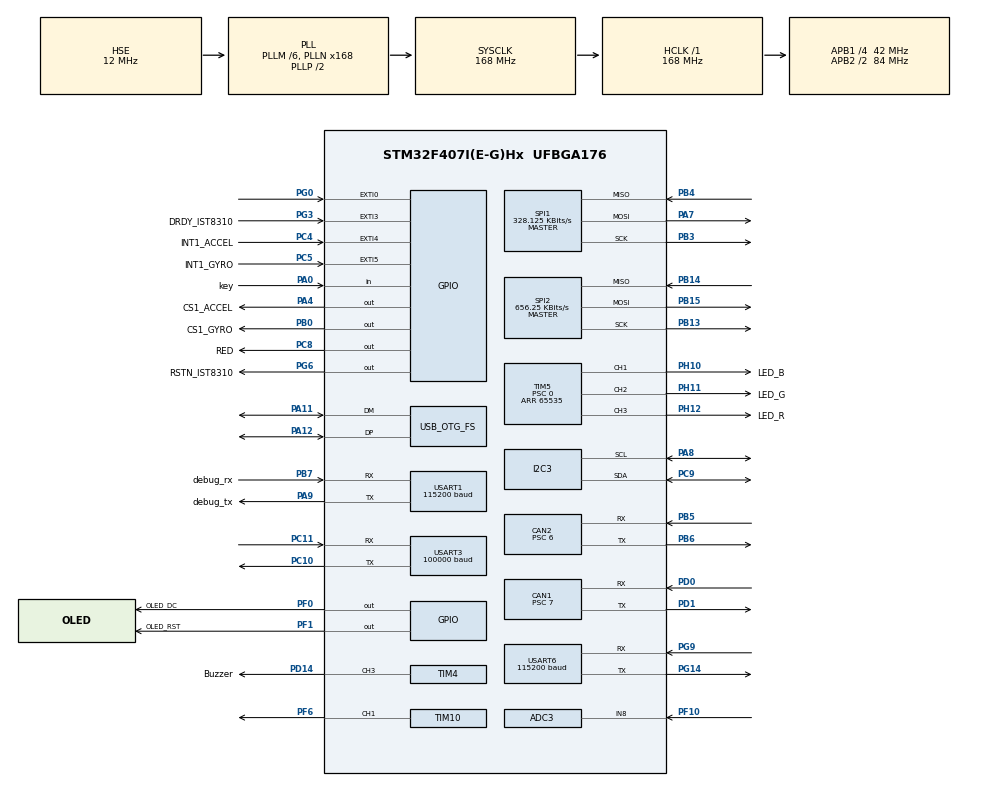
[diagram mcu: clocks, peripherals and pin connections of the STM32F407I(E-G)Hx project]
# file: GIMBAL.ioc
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ADC1.Channel-0\#ChannelRegularConversion=ADC_CHANNEL_TEMPSENSOR
ADC1.NbrOfConversionFlag=1
ADC1.Rank-0\#ChannelRegularConversion=1
ADC1.SamplingTime-0\#ChannelRegularConversion=ADC_SAMPLETIME_3CYCLES
ADC1.master=1
ADC3.Channel-0\#ChannelRegularConversion=ADC_CHANNEL_8
ADC3.NbrOfConversionFlag=1
ADC3.Rank-0\#ChannelRegularConversion=1
ADC3.SamplingTime-0\#ChannelRegularConversion=ADC_SAMPLETIME_3CYCLES
CAN1.ABOM=ENABLE
CAN1.AWUM=ENABLE
CAN1.BS1=CAN_BS1_3TQ
CAN1.BS2=CAN_BS2_2TQ
CAN1.CalculateTimeQuantum=166.66666666666669
CAN1.NART=ENABLE
CAN1.Prescaler=7
CAN2.ABOM=ENABLE
CAN2.AWUM=ENABLE
CAN2.BS1=CAN_BS1_4TQ
CAN2.BS2=CAN_BS2_2TQ
CAN2.CalculateTimeQuantum=142.85714285714286
CAN2.Prescaler=6
Dma.Request0=SPI1_RX
Dma.Request1=SPI1_TX
Dma.Request2=USART1_TX
Dma.Request3=USART3_RX
Dma.Request4=USART1_RX
Dma.Request5=USART6_RX
Dma.Request6=USART6_TX
Dma.SPI1_RX.0.Direction=DMA_PERIPH_TO_MEMORY
Dma.SPI1_RX.0.FIFOMode=DMA_FIFOMODE_DISABLE
Dma.SPI1_RX.0.Instance=DMA2_Stream2
Dma.SPI1_RX.0.MemDataAlignment=DMA_MDATAALIGN_BYTE
Dma.SPI1_RX.0.MemInc=DMA_MINC_ENABLE
Dma.SPI1_RX.0.Mode=DMA_NORMAL
Dma.SPI1_RX.0.PeriphDataAlignment=DMA_PDATAALIGN_BYTE
Dma.SPI1_RX.0.PeriphInc=DMA_PINC_DISABLE
Dma.SPI1_RX.0.Priority=DMA_PRIORITY_VERY_HIGH
Dma.SPI1_TX.1.Direction=DMA_MEMORY_TO_PERIPH
Dma.SPI1_TX.1.FIFOMode=DMA_FIFOMODE_DISABLE
Dma.SPI1_TX.1.Instance=DMA2_Stream3
Dma.SPI1_TX.1.MemDataAlignment=DMA_MDATAALIGN_BYTE
Dma.SPI1_TX.1.MemInc=DMA_MINC_ENABLE
Dma.SPI1_TX.1.Mode=DMA_NORMAL
Dma.SPI1_TX.1.PeriphDataAlignment=DMA_PDATAALIGN_BYTE
Dma.SPI1_TX.1.PeriphInc=DMA_PINC_DISABLE
Dma.SPI1_TX.1.Priority=DMA_PRIORITY_HIGH
Dma.USART1_RX.4.Direction=DMA_PERIPH_TO_MEMORY
Dma.USART1_RX.4.FIFOMode=DMA_FIFOMODE_DISABLE
Dma.USART1_RX.4.Instance=DMA2_Stream5
Dma.USART1_RX.4.MemDataAlignment=DMA_MDATAALIGN_BYTE
Dma.USART1_RX.4.MemInc=DMA_MINC_ENABLE
Dma.USART1_RX.4.Mode=DMA_CIRCULAR
Dma.USART1_RX.4.PeriphDataAlignment=DMA_PDATAALIGN_BYTE
Dma.USART1_RX.4.PeriphInc=DMA_PINC_DISABLE
Dma.USART1_RX.4.Priority=DMA_PRIORITY_LOW
Dma.USART1_TX.2.Direction=DMA_MEMORY_TO_PERIPH
Dma.USART1_TX.2.FIFOMode=DMA_FIFOMODE_DISABLE
Dma.USART1_TX.2.Instance=DMA2_Stream7
Dma.USART1_TX.2.MemDataAlignment=DMA_MDATAALIGN_BYTE
Dma.USART1_TX.2.MemInc=DMA_MINC_ENABLE
Dma.USART1_TX.2.Mode=DMA_NORMAL
Dma.USART1_TX.2.PeriphDataAlignment=DMA_PDATAALIGN_BYTE
Dma.USART1_TX.2.PeriphInc=DMA_PINC_DISABLE
Dma.USART1_TX.2.Priority=DMA_PRIORITY_LOW
Dma.USART3_RX.3.Direction=DMA_PERIPH_TO_MEMORY
Dma.USART3_RX.3.FIFOMode=DMA_FIFOMODE_DISABLE
Dma.USART3_RX.3.Instance=DMA1_Stream1
Dma.USART3_RX.3.MemDataAlignment=DMA_MDATAALIGN_BYTE
Dma.USART3_RX.3.MemInc=DMA_MINC_ENABLE
Dma.USART3_RX.3.Mode=DMA_CIRCULAR
Dma.USART3_RX.3.PeriphDataAlignment=DMA_PDATAALIGN_BYTE
Dma.USART3_RX.3.PeriphInc=DMA_PINC_DISABLE
Dma.USART3_RX.3.Priority=DMA_PRIORITY_MEDIUM
Dma.USART6_RX.5.Direction=DMA_PERIPH_TO_MEMORY
Dma.USART6_RX.5.FIFOMode=DMA_FIFOMODE_DISABLE
Dma.USART6_RX.5.Instance=DMA2_Stream1
Dma.USART6_RX.5.MemDataAlignment=DMA_MDATAALIGN_BYTE
Dma.USART6_RX.5.MemInc=DMA_MINC_ENABLE
Dma.USART6_RX.5.Mode=DMA_CIRCULAR
Dma.USART6_RX.5.PeriphDataAlignment=DMA_PDATAALIGN_BYTE
Dma.USART6_RX.5.PeriphInc=DMA_PINC_DISABLE
Dma.USART6_RX.5.Priority=DMA_PRIORITY_MEDIUM
Dma.USART6_TX.6.Direction=DMA_MEMORY_TO_PERIPH
Dma.USART6_TX.6.FIFOMode=DMA_FIFOMODE_DISABLE
Dma.USART6_TX.6.Instance=DMA2_Stream6
Dma.USART6_TX.6.MemDataAlignment=DMA_MDATAALIGN_BYTE
Dma.USART6_TX.6.MemInc=DMA_MINC_ENABLE
Dma.USART6_TX.6.Mode=DMA_NORMAL
Dma.USART6_TX.6.PeriphDataAlignment=DMA_PDATAALIGN_BYTE
Dma.USART6_TX.6.PeriphInc=DMA_PINC_DISABLE
Dma.USART6_TX.6.Priority=DMA_PRIORITY_HIGH
FREERTOS.INCLUDE_eTaskGetState=1
FREERTOS.INCLUDE_pcTaskGetTaskName=1
FREERTOS.INCLUDE_uxTaskGetStackHighWaterMark=1
FREERTOS.INCLUDE_vTaskCleanUpResources=1
FREERTOS.INCLUDE_vTaskDelayUntil=1
FREERTOS.INCLUDE_xEventGroupSetBitFromISR=1
FREERTOS.INCLUDE_xQueueGetMutexHolder=1
FREERTOS.INCLUDE_xSemaphoreGetMutexHolder=1
FREERTOS.INCLUDE_xTaskAbortDelay=1
FREERTOS.INCLUDE_xTaskGetCurrentTaskHandle=1
FREERTOS.INCLUDE_xTaskGetHandle=1
FREERTOS.INCLUDE_xTimerPendFunctionCall=1
FREERTOS.Tasks01=test,0,128,test_task,As weak,NULL,Dynamic,NULL,NULL;Debug_Task,0,128,Debug,Default,NULL,Dynamic,NULL,NULL;IMU_Send_Task,2,128,IMU_Send,Default,NULL,Dynamic,NULL,NULL;Can2_Rei_Task,1,128,Can2_Reivece,Default,NULL,Dynamic,NULL,NULL;CAN1,1,128,CAN1_R,Default,NULL,Dynamic,NULL,NULL
FREERTOS.configTOTAL_HEAP_SIZE=24576
I2C3.I2C_Mode=I2C_Fast
Mcu.Family=STM32F4
Mcu.Name=STM32F407I(E-G)Hx
Mcu.Package=UFBGA176
NVIC.CAN1_RX0_IRQn=true\:5\:0\:true\:false\:true\:true\:true\:true
NVIC.CAN2_RX0_IRQn=true\:5\:0\:true\:false\:true\:true\:true\:true
NVIC.DMA1_Stream1_IRQn=true\:0\:0\:false\:false\:true\:false\:true\:true
NVIC.DMA2_Stream1_IRQn=true\:0\:0\:false\:false\:true\:true\:false\:true
NVIC.DMA2_Stream2_IRQn=true\:5\:0\:true\:false\:false\:true\:false\:true
NVIC.DMA2_Stream3_IRQn=true\:5\:0\:true\:false\:false\:true\:false\:true
NVIC.DMA2_Stream5_IRQn=true\:0\:0\:false\:false\:true\:true\:false\:true
NVIC.DMA2_Stream6_IRQn=true\:0\:0\:false\:false\:true\:true\:false\:true
NVIC.DMA2_Stream7_IRQn=true\:0\:0\:false\:false\:true\:false\:true\:true
NVIC.EXTI0_IRQn=true\:6\:0\:true\:false\:true\:true\:true\:true
NVIC.EXTI3_IRQn=true\:5\:0\:true\:false\:true\:true\:true\:true
NVIC.EXTI4_IRQn=true\:5\:0\:true\:false\:true\:true\:true\:true
NVIC.EXTI9_5_IRQn=true\:5\:0\:true\:false\:true\:true\:true\:true
NVIC.OTG_FS_IRQn=true\:5\:0\:true\:false\:true\:true\:true\:true
NVIC.PriorityGroup=NVIC_PRIORITYGROUP_4
NVIC.TIM3_IRQn=true\:7\:0\:true\:false\:true\:true\:true\:true
NVIC.TIM6_DAC_IRQn=true\:0\:0\:false\:false\:true\:false\:true\:true
NVIC.TimeBase=TIM6_DAC_IRQn
NVIC.TimeBaseIP=TIM6
NVIC.USART1_IRQn=true\:6\:0\:true\:false\:true\:true\:true\:true
NVIC.USART3_IRQn=true\:6\:0\:true\:false\:true\:true\:true\:true
NVIC.USART6_IRQn=true\:6\:0\:true\:false\:true\:true\:true\:true
PA0-WKUP.GPIO_Label=key
PA0-WKUP.GPIO_PuPd=GPIO_PULLUP
PA0-WKUP.Signal=GPIO_Input
PA11.Mode=Device_Only
PA11.Signal=USB_OTG_FS_DM
PA12.Mode=Device_Only
PA12.Signal=USB_OTG_FS_DP
PA13.Mode=Serial_Wire
PA13.Signal=SYS_JTMS-SWDIO
PA14.Mode=Serial_Wire
PA14.Signal=SYS_JTCK-SWCLK
PA4.GPIO_Label=CS1_ACCEL
PA4.GPIO_PuPd=GPIO_PULLUP
PA4.GPIO_Speed=GPIO_SPEED_FREQ_HIGH
PA4.PinState=GPIO_PIN_SET
PA4.Signal=GPIO_Output
PA7.GPIO_PuPd=GPIO_PULLUP
PA7.Mode=Full_Duplex_Master
PA7.Signal=SPI1_MOSI
PA8.Mode=I2C
PA8.Signal=I2C3_SCL
PA9.GPIO_Label=debug_tx
PA9.Mode=Asynchronous
PA9.Signal=USART1_TX
PB0.GPIO_Label=CS1_GYRO
PB0.GPIO_PuPd=GPIO_PULLUP
PB0.GPIO_Speed=GPIO_SPEED_FREQ_HIGH
PB0.PinState=GPIO_PIN_SET
PB0.Signal=GPIO_Output
PB12.Signal=SPI2_NSS
PB13.Mode=Full_Duplex_Master
PB13.Signal=SPI2_SCK
PB14.Mode=Full_Duplex_Master
PB14.Signal=SPI2_MISO
PB15.Mode=Full_Duplex_Master
PB15.Signal=SPI2_MOSI
PB3.GPIO_PuPd=GPIO_PULLUP
PB3.Mode=Full_Duplex_Master
PB3.Signal=SPI1_SCK
PB4.GPIO_PuPd=GPIO_PULLUP
PB4.Mode=Full_Duplex_Master
PB4.Signal=SPI1_MISO
PB5.Mode=Slave
PB5.Signal=CAN2_RX
PB6.Mode=Slave
PB6.Signal=CAN2_TX
PB7.GPIO_Label=debug_rx
PB7.Mode=Asynchronous
PB7.Signal=USART1_RX
PC10.Mode=Asynchronous
PC10.Signal=USART3_TX
PC11.Mode=Asynchronous
PC11.Signal=USART3_RX
PC4.GPIO_Label=INT1_ACCEL
PC4.GPIO_ModeDefaultEXTI=GPIO_MODE_IT_FALLING
PC4.GPIO_PuPd=GPIO_PULLUP
PC4.Signal=GPXTI4
PC5.GPIO_Label=INT1_GYRO
PC5.GPIO_ModeDefaultEXTI=GPIO_MODE_IT_FALLING
PC5.GPIO_PuPd=GPIO_PULLUP
PC5.Signal=GPXTI5
PC8.GPIO_Label=RED
PC8.GPIO_PuPd=GPIO_NOPULL
PC8.GPIO_Speed=GPIO_SPEED_FREQ_MEDIUM
PC8.Signal=GPIO_Output
PC9.Mode=I2C
PC9.Signal=I2C3_SDA
PD0.Mode=Master
PD0.Signal=CAN1_RX
PD1.Mode=Master
PD1.Signal=CAN1_TX
PD14.GPIO_Label=Buzzer
PD14.Signal=S_TIM4_CH3
PF0.GPIO_Label=OLED_DC
PF0.Signal=GPIO_Output
PF1.GPIO_Label=OLED_RST
PF1.Signal=GPIO_Output
PF10.Mode=IN8
PF10.Signal=ADC3_IN8
PF6.GPIO_PuPd=GPIO_PULLUP
PF6.GPIO_Speed=GPIO_SPEED_FREQ_HIGH
PF6.Signal=S_TIM10_CH1
PG0.GPIO_ModeDefaultEXTI=GPIO_MODE_IT_FALLING
PG0.GPIO_PuPd=GPIO_PULLUP
PG0.Signal=GPXTI0
PG14.Mode=Asynchronous
PG14.Signal=USART6_TX
PG3.GPIO_Label=DRDY_IST8310
PG3.GPIO_ModeDefaultEXTI=GPIO_MODE_IT_FALLING
PG3.GPIO_PuPd=GPIO_PULLUP
PG3.Signal=GPXTI3
PG6.GPIO_Label=RSTN_IST8310
PG6.GPIO_PuPd=GPIO_PULLUP
PG6.GPIO_Speed=GPIO_SPEED_FREQ_MEDIUM
PG6.PinState=GPIO_PIN_SET
PG6.Signal=GPIO_Output
PG9.Mode=Asynchronous
PG9.Signal=USART6_RX
PH0-OSC_IN.Mode=HSE-External-Oscillator
PH0-OSC_IN.Signal=RCC_OSC_IN
PH1-OSC_OUT.Mode=HSE-External-Oscillator
PH1-OSC_OUT.Signal=RCC_OSC_OUT
PH10.GPIO_Label=LED_B
PH10.GPIO_PuPd=GPIO_PULLUP
PH10.GPIO_Speed=GPIO_SPEED_FREQ_HIGH
PH10.Signal=S_TIM5_CH1
PH11.GPIO_Label=LED_G
PH11.GPIO_PuPd=GPIO_PULLUP
PH11.GPIO_Speed=GPIO_SPEED_FREQ_HIGH
PH11.Signal=S_TIM5_CH2
PH12.GPIO_Label=LED_R
PH12.GPIO_PuPd=GPIO_PULLUP
PH12.GPIO_Speed=GPIO_SPEED_FREQ_HIGH
PH12.Signal=S_TIM5_CH3
ProjectManager.HeapSize=0x2000
ProjectManager.StackSize=0x2000
ProjectManager.TargetToolchain=MDK-ARM V5
RCC.48MHZClocksFreq_Value=48000000
RCC.AHBFreq_Value=168000000
RCC.APB1CLKDivider=RCC_HCLK_DIV4
RCC.APB1Freq_Value=42000000
RCC.APB1TimFreq_Value=84000000
RCC.APB2CLKDivider=RCC_HCLK_DIV2
RCC.APB2Freq_Value=84000000
RCC.APB2TimFreq_Value=168000000
RCC.CortexFreq_Value=168000000
RCC.HCLKFreq_Value=168000000
RCC.HSE_VALUE=12000000
RCC.HSI_VALUE=16000000
RCC.LSE_VALUE=32768
RCC.PLLM=6
RCC.PLLN=168
RCC.PLLQ=7
RCC.RCC_RTC_Clock_SourceVirtual=RCC_RTCCLKSOURCE_HSE_DIV30
RCC.RCC_RTC_Clock_Source_FROM_HSE=RCC_RTCCLKSOURCE_HSE_DIV30
RCC.SYSCLKFreq_VALUE=168000000
RCC.SYSCLKSource=RCC_SYSCLKSOURCE_PLLCLK
RCC.VCOOutputFreq_Value=336000000
SH.S_TIM10_CH1.0=TIM10_CH1,PWM Generation1 CH1
SH.S_TIM4_CH3.0=TIM4_CH3,PWM Generation3 CH3
SH.S_TIM5_CH1.0=TIM5_CH1,PWM Generation1 CH1
SH.S_TIM5_CH2.0=TIM5_CH2,PWM Generation2 CH2
SH.S_TIM5_CH3.0=TIM5_CH3,PWM Generation3 CH3
SPI1.BaudRatePrescaler=SPI_BAUDRATEPRESCALER_256
SPI1.CLKPhase=SPI_PHASE_2EDGE
SPI1.CLKPolarity=SPI_POLARITY_HIGH
SPI1.CalculateBaudRate=328.125 KBits/s
SPI1.Direction=SPI_DIRECTION_2LINES
SPI1.Mode=SPI_MODE_MASTER
SPI1.VirtualType=VM_MASTER
SPI2.BaudRatePrescaler=SPI_BAUDRATEPRESCALER_64
SPI2.CalculateBaudRate=656.25 KBits/s
SPI2.Direction=SPI_DIRECTION_2LINES
SPI2.Mode=SPI_MODE_MASTER
SPI2.VirtualType=VM_MASTER
TIM10.Channel=TIM_CHANNEL_1
TIM10.Period=4999
TIM3.AutoReloadPreload=TIM_AUTORELOAD_PRELOAD_ENABLE
TIM3.Period=49
TIM3.Prescaler=83
TIM4.Channel-PWM\ Generation3\ CH3=TIM_CHANNEL_3
TIM4.Period=370
TIM4.Prescaler=130
TIM4.Pulse-PWM\ Generation3\ CH3=0
TIM5.Channel-PWM\ Generation1\ CH1=TIM_CHANNEL_1
TIM5.Channel-PWM\ Generation2\ CH2=TIM_CHANNEL_2
TIM5.Channel-PWM\ Generation3\ CH3=TIM_CHANNEL_3
TIM5.Period=65535
TIM5.Prescaler=0
USART1.BaudRate=115200
USART1.VirtualMode=VM_ASYNC
USART3.BaudRate=100000
USART3.VirtualMode=VM_ASYNC
USART6.BaudRate=115200
USART6.VirtualMode=VM_ASYNC
USB_DEVICE.CLASS_NAME_FS=CDC
USB_DEVICE.VirtualMode-CDC_FS=Cdc
USB_DEVICE.VirtualModeFS=Cdc_FS
USB_OTG_FS.VirtualMode=Device_Only
VP_ADC1_TempSens_Input.Mode=IN-TempSens
VP_ADC1_Vref_Input.Mode=IN-Vrefint
VP_FREERTOS_VS_CMSIS_V1.Mode=CMSIS_V1
VP_SYS_VS_tim6.Mode=TIM6
VP_TIM10_VS_ClockSourceINT.Mode=Enable_Timer
VP_TIM3_VS_ClockSourceINT.Mode=Internal
VP_TIM4_VS_ClockSourceINT.Mode=Internal
VP_TIM5_VS_ClockSourceINT.Mode=Internal
VP_USB_DEVICE_VS_USB_DEVICE_CDC_FS.Mode=CDC_FS
board=custom

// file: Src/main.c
/* USER CODE BEGIN Header */
/**
  ******************************************************************************
  * @file           : main.c
  * @brief          : Main program body
  ******************************************************************************
  * @attention
  *
  * <h2><center>&copy; Copyright (c) 2019 STMicroelectronics.
  * All rights reserved.</center></h2>
  *
  * This software component is licensed by ST under Ultimate Liberty license
  * SLA0044, the "License"; You may not use this file except in compliance with
  * the License. You may obtain a copy of the License at:
  *                             www.st.com/SLA0044
  *
  ******************************************************************************
  */
/* USER CODE END Header */
#include "main.h"
#include "cmsis_os.h"
#include "adc.h"
#include "can.h"
#include "dma.h"
#include "i2c.h"
#include "spi.h"
#include "tim.h"
#include "usart.h"
#include "usb_device.h"
#include "gpio.h"

/* USER CODE BEGIN Includes */
#include "bsp_delay.h"

#include "calibrate_task.h"
#include "INS_task.h"
#include "led_flow_task.h"
#include "user_can.h"
#include "bsp_buzzer.h"
#include "stdbool.h"
#include "DR16_RECIVE.h"
#include "oled.h"
#include "bsp_adc.h"
#include "stdio.h"

//#include "oledfont.h"
/* USER CODE END Includes */

void SystemClock_Config(void);
void MX_FREERTOS_Init(void);

/* USER CODE BEGIN 0 */
bool ins_ok=0;
int controul_times=0;
int ins_times=0;
int DR16_times=0;
int M2006_times=0;

int send_to_2006=0;
int M2006_targe_speed=0;
int beep_Val=0;

	int	send_to_SHOOT_R=0;
	int	send_to_SHOOT_L=0;
	int	send_to_tire_R=0;/*右轮*/
	int	send_to_tire_L=0;/*左轮*/

int SHOOT_L_speed=0;//左摩擦轮的目标速度   应该为负值
int SHOOT_R_speed=0;//右摩擦轮的目标速度

int tire_L_TARGE_speed=0;//左轮的目标速度   应该为负值?
int tire_R_TARGE_speed=0;//右轮的目标速度

int tire_L_TARGE_speed_FAKE=0;//左轮的目标速度 (假)  应该为负值?
int tire_R_TARGE_speed_FAKE=0;//右轮的目标速度

int yaw_trage_speed=0;
float yaw_trage_angle=0;
float yaw_trage_angle_1s_ago=0;
float yaw_trage_angle_add_1s=0;

int send_to_yaw=0;

int send_to_pitch=0;//发送给pitch轴的数据

float PITCH_MAX_angle=0;
float PITCH_MIN_angle=0;
float allow_angle=0;//可动区间

float PITCH_trage_angle=0;
float PITCH_trage_angle_motor=4500.0;

int PITCH_trage_speed=0;

int can1_IT_TIMES=0;

int can2_DR16_TIMES=0;
int can2_IT_TIMES=0;
int CH0_TOTAL=0;
int CH0_TOTAL_in_con=0;

int CH1_TOTAL=0;
int CH2_TOTAL=0;
int CH3_TOTAL=0;

int JS_RC_TIMES=0;
bool run_JS_jiema;

int STATUS_PART_ONE_TIMES=0;
int STATUS_PART_TWO_TIMES=0;
int STATUS_PART_THREE_TIMES=0;
int STATUS_PART_FOUR_TIMES=0;
int STATUS_complete_update_TIMES=0;//裁判系统状态信息更新成功次数

int HP_complete_update_TIMES=0;//裁判系统状态信息更新成功次数

int HEAT_complete_update_TIMES=0;//裁判系统热量信息更新成功次数
int place_complete_update_TIMES=0;//裁判系统热量信息更新成功次数

int GAME_STATE_update_TIMES=0;//裁判系统比赛状态信息更新成功次数

int DDR16_PART_ONE_TIMES=0;
int DDR16_PART_TWO_TIMES=0;
int DDR16_PART_THREE_TIMES=0;
int dr16_controul_times=0;
bool run_DR16_jiema;

float Vision_RawData_Yaw_Angle=0;
float Vision_RawData_Pitch_Angle=0;
volatile unsigned long long FreeRTOSRunTimeTicks;

int TEST_Current_L=0;
int TEST_Current_R=0;

int CLOUD_enable_moto=0;
float CLOUD_enable_imu=0;
bool cloud_text_add=1;
bool cloud_enable=0;
int VISION_FROM_USART1=0;
int VISION_Disconnect_test=0;
int Armour_lose_time=0;
int SHOOT_STOP_time=0;

int vision_shoot_times;
int shoot_times_for_limit=0;//发射周期(为了热量限制)
bool whether_shoot_in__this_period=0;//这个周期是否发射
bool this_period_has_shoot=0;//这个周期是否发射

int this_period_has_shoot_number=0;//这个周期发射shu
int every_shoot_number=600;//一次三十发
int targe_shoot_number=0;//一次三十发

bool disable_for_test=0;//为了调试
int ch4_DW_total=0;
int ch4_DW_total_2=0;

bool crc_right=0;
int vision_rc_right=0;
int vision_rc_error=0;

int CAN2_rc_times=0;

float simulation_target_yaw=0;

bool TEMPERATURE_is_OK=0;
int TEMPERATURE_PID_OUT=0;

bool in_MID=1;//处在轨道中间段
bool in_END=0;//处在轨道尽头
bool in_END_last=0;//上一时刻处在轨道尽头

bool in_END_R=0;//处在右轨道尽头
bool in_END_L=0;//处在左轨道尽头

bool disable_for_test_CHASSIS=0;

float my_voltage;

int stay_in_track_end_times=0;
int text_times=0;
bool send_to_vision_1=0;

int hurt_times_ago=100000;
int laoliu_gjiwo_times_ago=100000;//老六攻击我
float jia_ZJ_YAW=0;
float jia_ZJ_PITCH=-40.0;
bool vision_beats_give_to_jia=0;

/*假装甲要用到GEBIN*/
 int8_t whether_use_fake_armor=0;
int fake_armor_init_angle_6020=0;
int fake_armor_init_place_encoder=0;
int fake_armor_vertical_place_encoder=0;

int fake_armor_init_vision_deepth=0;/*mm*/
int fake_armor_vertica_distance=0;/*垂直距离mm*/

float fake_armor_now_angle_IMU=0.0;

float YAW_TRAGET_ANGLE_TEMP_FAKE_MOTO;
float YAW_TRAGET_ANGLE_TEMP_FAKE_IMU;

float send_to_pitch_before=0;
/*假装甲要用到END*/

int MIT_RC_TIMES=0;
int MIT_RC_Process_TIMES=0;

int calibration_times=0;//校准累计计时
int flash_read_times=0;//flash读取累计计时

bool send_to_C;//DR16_遥控器_是否发送给C板
int send_to_C_times;//dr16发送次数

bool open_CHASSIS_follow=1;//开启底盘跟随云台这个功能
int CHASSIS_follow_times=0;//底盘跟随云台时间

/*
机器人状态数据，10Hz 周期发送                              27(15)
实时功率热量数据，50Hz 周期发送                            16(14)
伤害状态数据，伤害发生后发送                               1
实时射击数据，子弹发射后发送                               6
子弹剩余发送数，空中机器人以及哨兵机器人发送，1Hz 周期发送   2
*/
bool send_to_C_JS_SHOOT;//裁判系统_发射数据_是否发送给C板
bool send_to_C_JS_HURT;//裁判系统_伤害数据_是否发送给C板
bool send_to_C_JS_STATUS;//裁判系统_状态数据_是否发送给C板
bool send_to_C_JS_HEAT=0;//裁判系统_状态数据_是否发送给C板

int JS_SEND_times=0;//裁判系统发送次数
int send_to_C_STATUS_times=0;//因为状态数据分4段发送,所以计数保险一点
int JS_RC_times=0;///裁判系统接收次数

/* USER CODE END 0 */

int main(void)
{

  /* MCU Configuration--------------------------------------------------------*/

  /* Reset of all peripherals, Initializes the Flash interface and the Systick. */
  HAL_Init();

  /* Configure the system clock */
  SystemClock_Config();

  /* Initialize all configured peripherals */
  MX_GPIO_Init();
  MX_DMA_Init();
  MX_SPI1_Init();
  MX_TIM5_Init();
  MX_I2C3_Init();
  MX_TIM10_Init();
  MX_USART1_UART_Init();
  MX_CAN2_Init();
  MX_TIM4_Init();
  MX_USART3_UART_Init();
  MX_CAN1_Init();
  MX_TIM3_Init();
  MX_USART6_UART_Init();
  MX_SPI2_Init();
  MX_ADC1_Init();
  MX_ADC3_Init();
  /* USER CODE BEGIN 2 */
	  delay_init();
		Buzzer_Init();
//					Buzzer.status = ON;

    cali_param_init();
   usart1_dr16_init();
   #ifdef FREERTOS_TASK_TIME
       HAL_TIM_Base_Start_IT(&htim3);
#endif
  oled_init();
  HAL_Delay(500);

    oled_clear(Pen_Clear);
    oled_LOGO();
    oled_refresh_gram();

    //use vrefint voltage to calibrate
    //使用基准电压来校准
    init_vrefint_reciprocal();

//CAN1_Config();
  /* USER CODE END 2 */

  /* Call init function for freertos objects (in freertos.c) */
  MX_FREERTOS_Init();
  /* Start scheduler */
  osKernelStart();

  /* We should never get here as control is now taken by the scheduler */
  /* Infinite loop */
  while (1)
  {

  }
}

void SystemClock_Config(void)
{
  RCC_OscInitTypeDef RCC_OscInitStruct = {0};
  RCC_ClkInitTypeDef RCC_ClkInitStruct = {0};

  /** Configure the main internal regulator output voltage
  */
  __HAL_RCC_PWR_CLK_ENABLE();
  __HAL_PWR_VOLTAGESCALING_CONFIG(PWR_REGULATOR_VOLTAGE_SCALE1);
  /** Initializes the RCC Oscillators according to the specified parameters
  * in the RCC_OscInitTypeDef structure.
  */
  RCC_OscInitStruct.OscillatorType = RCC_OSCILLATORTYPE_HSE;
  RCC_OscInitStruct.HSEState = RCC_HSE_ON;
  RCC_OscInitStruct.PLL.PLLState = RCC_PLL_ON;
  RCC_OscInitStruct.PLL.PLLSource = RCC_PLLSOURCE_HSE;
  RCC_OscInitStruct.PLL.PLLM = 6;
  RCC_OscInitStruct.PLL.PLLN = 168;
  RCC_OscInitStruct.PLL.PLLP = RCC_PLLP_DIV2;
  RCC_OscInitStruct.PLL.PLLQ = 7;
  if (HAL_RCC_OscConfig(&RCC_OscInitStruct) != HAL_OK)
  {
    Error_Handler();
  }
  /** Initializes the CPU, AHB and APB buses clocks
  */
  RCC_ClkInitStruct.ClockType = RCC_CLOCKTYPE_HCLK|RCC_CLOCKTYPE_SYSCLK
                              |RCC_CLOCKTYPE_PCLK1|RCC_CLOCKTYPE_PCLK2;
  RCC_ClkInitStruct.SYSCLKSource = RCC_SYSCLKSOURCE_PLLCLK;
  RCC_ClkInitStruct.AHBCLKDivider = RCC_SYSCLK_DIV1;
  RCC_ClkInitStruct.APB1CLKDivider = RCC_HCLK_DIV4;
  RCC_ClkInitStruct.APB2CLKDivider = RCC_HCLK_DIV2;

  if (HAL_RCC_ClockConfig(&RCC_ClkInitStruct, FLASH_LATENCY_5) != HAL_OK)
  {
    Error_Handler();
  }
}

/* USER CODE BEGIN 4 */
//初始化TIM3使其为FreeRTOS的时间统计提供时基
void ConfigureTimeForRunTimeStats(void)
{
	//定时器3初始化，定时器时钟为84M，分频系数为84-1，所以定时器3的频率
	//为84M/84=1M，自动重装载为50-1，那么定时器周期就是50us
	FreeRTOSRunTimeTicks=0;
//	TIM3_Int_Init(50-1,84-1);	//初始化TIM3
}

//int fputc(int ch, FILE *f)
//{
// uint8_t temp[1] = {ch};
// HAL_UART_Transmit(&huart1, temp, 1, 100);
// return ch;
//}

/* USER CODE END 4 */

void HAL_TIM_PeriodElapsedCallback(TIM_HandleTypeDef *htim)
{
  if (htim->Instance == TIM6) {
    HAL_IncTick();
  }
}

void Error_Handler(void)
{
}

/************************ (C) COPYRIGHT STMicroelectronics *****END OF FILE****/

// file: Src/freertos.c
/* USER CODE BEGIN Header */
/**
 ******************************************************************************
 * File Name          : freertos.c
 * Description        : Code for freertos applications
 ******************************************************************************
 * @attention
 *
 * <h2><center>&copy; Copyright (c) 2019 STMicroelectronics.
 * All rights reserved.</center></h2>
 *
 * This software component is licensed by ST under Ultimate Liberty license
 * SLA0044, the "License"; You may not use this file except in compliance with
 * the License. You may obtain a copy of the License at:
 *                             www.st.com/SLA0044
 *
 ******************************************************************************
 */
/* USER CODE END Header */

#include "FreeRTOS.h"
#include "task.h"
#include "main.h"
#include "cmsis_os.h"

/* USER CODE BEGIN Includes */

#include "calibrate_task.h"

#include "INS_task.h"
#include "led_flow_task.h"
#include "usbd_cdc_if.h"

#include "Debug_DataScope.h"
#include "DJI_IMU.h"
#include "bsp_buzzer.h"
#include "M3508.h"
#include "M2006.h"
#include "my_IncrementPID_bate.h"
#include "DR16_RECIVE.h"
#include "my_positionPID_bate.h"
#include "GM6020.h"
#include "MY_CLOUD_CONTROL.h"
#include "MY_SHOOT_CONTROL.h"
#include "BEEP_MY.h"
#include "bsp_buzzer.h"
#include "Vision.h"
#include "string.h"
#include "FPS_Calculate.h"
#include "bsp_adc.h"
#include "oled.h"
#include "spinning_top_examine.h"
#include "Vision_Control.h"
#include "MY_CLOUD_CONTROL.h"
// #include "usbd_cdc_if.h"
#include "MY_balance_CONTROL.h"
#include "LPF.h"
#include "CAN2_SEND.h"
#include "MIT.h"
#include "MIT_INIT.h"
#include "LQR_TEST.h"
#include "mit_math.h"
#include "keyBoard_to_vjoy.h"
#include "DR16_CAN2_SEND.h"
#include "CHASSIS_follow.h"
#include "ROW_balance.h"
#include "MF9025.h"
#include "RM_JudgeSystem.h"
#include "CAN2_SEND_RM.h"

/* USER CODE END Includes */

/* USER CODE BEGIN PTD */

osThreadId calibrate_tast_handle;
osThreadId imuTaskHandle;
osThreadId led_RGB_flow_handle;

/* USER CODE END PTD */

/* USER CODE BEGIN Variables */
// CAN队列句柄
osMessageQId CAN1_Queue;

osMessageQId CAN2_Queue;

// 控制任务句柄
osThreadId RobotCtrl_Handle;
// 任务入口函数
void Robot_Control(void const *argument);

/* USER CODE END Variables */
osThreadId testHandle;
osThreadId Debug_TaskHandle;
osThreadId IMU_Send_TaskHandle;
osThreadId Can2_Rei_TaskHandle;
osThreadId CAN1Handle;

void test_task(void const *argument);
void Debug(void const *argument);
void IMU_Send(void const *argument);
void Can2_Reivece(void const *argument);
void CAN1_R(void const *argument);

extern void MX_USB_DEVICE_Init(void);
void MX_FREERTOS_Init(void); /* (MISRA C 2004 rule 8.1) */

/* GetIdleTaskMemory prototype (linked to static allocation support) */
void vApplicationGetIdleTaskMemory(StaticTask_t **ppxIdleTaskTCBBuffer, StackType_t **ppxIdleTaskStackBuffer, uint32_t *pulIdleTaskStackSize);

/* GetTimerTaskMemory prototype (linked to static allocation support) */
void vApplicationGetTimerTaskMemory(StaticTask_t **ppxTimerTaskTCBBuffer, StackType_t **ppxTimerTaskStackBuffer, uint32_t *pulTimerTaskStackSize);

/* USER CODE BEGIN GET_IDLE_TASK_MEMORY */
static StaticTask_t xIdleTaskTCBBuffer;
static StackType_t xIdleStack[configMINIMAL_STACK_SIZE];

void vApplicationGetIdleTaskMemory(StaticTask_t **ppxIdleTaskTCBBuffer, StackType_t **ppxIdleTaskStackBuffer, uint32_t *pulIdleTaskStackSize)
{
	*ppxIdleTaskTCBBuffer = &xIdleTaskTCBBuffer;
	*ppxIdleTaskStackBuffer = &xIdleStack[0];
	*pulIdleTaskStackSize = configMINIMAL_STACK_SIZE;
	/* place for user code */
}
/* USER CODE END GET_IDLE_TASK_MEMORY */

/* USER CODE BEGIN GET_TIMER_TASK_MEMORY */
static StaticTask_t xTimerTaskTCBBuffer;
static StackType_t xTimerStack[configTIMER_TASK_STACK_DEPTH];

void vApplicationGetTimerTaskMemory(StaticTask_t **ppxTimerTaskTCBBuffer, StackType_t **ppxTimerTaskStackBuffer, uint32_t *pulTimerTaskStackSize)
{
	*ppxTimerTaskTCBBuffer = &xTimerTaskTCBBuffer;
	*ppxTimerTaskStackBuffer = &xTimerStack[0];
	*pulTimerTaskStackSize = configTIMER_TASK_STACK_DEPTH;
	/* place for user code */
}
/* USER CODE END GET_TIMER_TASK_MEMORY */

void MX_FREERTOS_Init(void)
{
	/* USER CODE BEGIN Init */
	I_PID_Parameter_Init(&Driver_I_PID, 4, 0.2, 5,
						 9000,		  // 积分分离
						 9000, -9000, // 最大误差
						 0.5,
						 9000, -9000,
						 10000, -10000); // 拨盘电机
	P_PID_Parameter_Init(&Driver_ANGLE_pid, 0.3, 0, 0,
						 3000,
						 // float max_error, float min_error,
						 //                           float alpha,
						 2000, -2000,
						 7000, -7000);

	I_PID_Parameter_Init(&SHOOT_L_I_PID, 28, 0.35, 15,
						 8700, 7000, -7000,
						 0.5,
						 14000, -14000,
						 16000, -16000); // 摩擦轮电机 37 0.35 13

	//
	I_PID_Parameter_Init(&SHOOT_R_I_PID, 28, 0.35, 15,
						 20000, 20000, -20000,
						 0.5,
						 14000, -14000,
						 16000, -16000); // 摩擦轮电机28 0.35 15
	// 23 0.5 19
	// 22 0.35 19

#if PID_MOTOR // 是否开启电机的PID
	P_PID_Parameter_Init(&Yaw_Speed_pid, 550, 10, 0,
						 120, // 误差大于这个值就积分分离
						 //	float max_error, float min_error,
						 //                          float alpha,
						 2000, -2000, // 积分限幅，也就是积分的输出范围
						 29000, -29000);
	P_PID_Parameter_Init(&Yaw_Angle_pid, 0.03, 0, 0,
						 0,
						 //						  float max_error, float min_error,
						 //                          float alpha,
						 0, 0,
						 220, -220); //

#endif

#if PID_YAW_IMU
	P_PID_Parameter_Init(&Yaw_IMU_Speed_pid, -800, -4, 800, //
						 60,								// 误差大于这个值就积分分离
						 //	float max_error, float min_error,
						 //                          float alpha,
						 0, -0, // 积分限幅，也就是积分的输出范围
						 29000, -29000);

	P_PID_Parameter_Init(&Yaw_IMU_Angle_pid, 8, 0, 0, // 10 0 16//越大越陡峭10
						 100,
						 //						  float max_error, float min_error,
						 //                          float alpha,
						 10, -10,
						 1000, -1000); // Yaw_IMU_Angle_pid
#endif

#if VISION_PID_YAW_IMU

	P_PID_Parameter_Init(&VISION_Yaw_IMU_Speed_pid, -900, -4.5, 800, //
						 60,										 // 误差大于这个值就积分分离
						 //	float max_error, float min_error,
						 //                          float alpha,
						 5000, -5000, // 积分限幅，也就是积分的输出范围
						 29000, -29000);

	P_PID_Parameter_Init(&VISION_Yaw_IMU_Angle_pid, 10, 0.085, 0, // 10 0 16//越大越陡峭10
						 2.8,
						 //						  float max_error, float min_error,
						 //                          float alpha,
						 600, -600,
						 1000, -1000); // Yaw_IMU_Angle_pid

#endif

#if use_new_gimbal == 0
#if PID_PITCH_MOTOR
	P_PID_Parameter_Init(&PITCH_Angle_pid, 0.45, 0, 0,
						 0, // 误差大于这个值就积分分离
						 //	float max_error, float min_error,
						 //                          float alpha,
						 220, -220, // 积分限幅，也就是积分的输出范围
						 220, -220);
	P_PID_Parameter_Init(&PITCH_Speed_pid, 300, 1, 0,
						 120,
						 //						  float max_error, float min_error,
						 //                          float alpha,
						 10000, -10000,	 // 积分限幅，也就是积分的输出范围
						 29000, -29000); // Yaw_IMU_Angle_pid
#endif

#endif
#if use_new_gimbal == 1
#if PID_PITCH_MOTOR
	P_PID_Parameter_Init(&PITCH_Angle_pid, 0.7, 0.05, 0,
						 0, // 误差大于这个值就积分分离
						 //	float max_error, float min_error,
						 //                          float alpha,
						 220, -220, // 积分限幅，也就是积分的输出范围
						 220, -220);
	P_PID_Parameter_Init(&PITCH_Speed_pid, 300, 1, 0,
						 120,
						 //						  float max_error, float min_error,
						 //                          float alpha,
						 10000, -10000,	 // 积分限幅，也就是积分的输出范围
						 29000, -29000); // Yaw_IMU_Angle_pid
#endif
#endif

#if 0 // 没电参数
	P_PID_Parameter_Init(&PITCH_IMU_Speed_pid, 200,0.4,0,//100, 1.5, 0,
						 15, //误差大于这个值就积分分离  550 1.9 0   -20000
						 //	float max_error, float min_error,
						 //                          float alpha,
						 3000, -3000, //积分限幅，也就是积分的输出范围    80    0.7        5000   -5000     28000   -28000
						 29000, -29000);
	P_PID_Parameter_Init(&PITCH_IMU_Angle_pid,12 //15  //0.7  12
	, 0.1, 0,
						 2.5,
						 //						  float max_error, float min_error,
						 //                          float alpha,
						 300, -300,
						 500, -500); // Yaw_IMU_Angle_pid   15    500 -500

#endif
#if PID_PITCH_IMU
	//	P_PID_Parameter_Init(&PITCH_IMU_Speed_pid, 150,0.3,0,//100, 1.5, 0,
	//						 25, //误差大于这个值就积分分离  550 1.9 0   -20000
	//						 //	float max_error, float min_error,
	//						 //                          float alpha,
	//						 4000, -4000, //积分限幅，也就是积分的输出范围    80    0.7        5000   -5000     28000   -28000
	//						 29000, -29000);

	P_PID_Parameter_Init(&PITCH_IMU_Speed_pid, 190, 0.9, -200, // 100, 1.5, 0,
						 100,								   // 误差大于这个值就积分分离  550 1.9 0   -20000
						 //	float max_error, float min_error,
						 //                          float alpha,
						 4000, -4000, // 积分限幅，也就是积分的输出范围    80    0.7        5000   -5000     28000   -28000
						 29000, -29000);
	P_PID_Parameter_Init(&PITCH_IMU_Angle_pid, 12 // 15  //0.7  12
						 ,
						 0.08, 0,
						 2.5,
						 //						  float max_error, float min_error,
						 //                          float alpha,
						 300, -300,
						 500, -500); // Yaw_IMU_Angle_pid   15    500 -500

#endif

	P_PID_Parameter_Init(&TIRE_L_SPEED_pid, 20 // 15  //0.7  12
						 ,
						 2,
						 40,
						 300,
						 //						  float max_error, float min_error,
						 //                          float alpha,
						 10000, -10000,
						 16000, -16000); // Yaw_IMU_Angle_pid   15    500 -500

	P_PID_Parameter_Init(&TIRE_R_SPEED_pid, 20 // 15  //0.7  12
						 ,
						 2,
						 40,
						 300,
						 //						  float max_error, float min_error,
						 //                          float alpha,
						 10000, -10000,
						 16000, -16000); // Yaw_IMU_Angle_pid   15    500 -500

#if 0 // 第一代参数
	P_PID_Parameter_Init(&BALANCE_P,280,0,0,4,//60,0.5,-30,0,
						 //						  float max_error, float min_error,
						 //                          float alpha,
						 700, -700,
						 14000, -14000); // 平衡PID
	P_PID_Parameter_Init(&BALANCE_I,40,0,0,0,//60,0.5,-30,0,
						 //						  float max_error, float min_error,
						 //                          float alpha,
						 500, -500,
						 14000, -14000); // 平衡PID
	P_PID_Parameter_Init(&SPEED_P,-0.8,-0.15,0,7300,//-0.5  -0.15软
						 //						  float max_error, float min_error,
						 //                          float alpha,
						 2000, -2000,
						 6000, -6000); // 速度PID

	P_PID_Parameter_Init(&change_direction_angle,6,0,0,0,//-0.5  -0.15软
						 //						  float max_error, float min_error,
						 //                          float alpha,
						 0, -0,
						 300, -300); // 转向环角度PID
	P_PID_Parameter_Init(&change_direction_speed,90,0,0,7300,//-0.5  -0.15软
						 //						  float max_error, float min_error,
						 //                          float alpha,
						 2000, -2000,
						 6000, -6000); // 转向环速度PID
#endif
#if 0 // 第2代参数
	P_PID_Parameter_Init(&BALANCE_P,280,0,0,4,//60,0.5,-30,0,
						 //						  float max_error, float min_error,
						 //                          float alpha,
						 700, -700,
						 14000, -14000); // 平衡PID
	P_PID_Parameter_Init(&BALANCE_I,40,0,0,0,//60,0.5,-30,0,
						 //						  float max_error, float min_error,
						 //                          float alpha,
						 500, -500,
						 14000, -14000); // 平衡PID
	P_PID_Parameter_Init(&SPEED_P,-0.5,-0.15,0,7300,//-0.5  -0.15软
						 //						  float max_error, float min_error,
						 //                          float alpha,
						 2000, -2000,
						 6000, -6000); // 速度PID

	P_PID_Parameter_Init(&change_direction_angle,6,0,0,0,//-0.5  -0.15软
						 //						  float max_error, float min_error,
						 //                          float alpha,
						 0, -0,
						 300, -300); // 转向环角度PID
	P_PID_Parameter_Init(&change_direction_speed,90,0,0,7300,//-0.5  -0.15软
						 //						  float max_error, float min_error,
						 //                          float alpha,
						 2000, -2000,
						 6000, -6000); // 转向环速度PID
#endif
#if 0 // 第3代参数 原地抽搐
	P_PID_Parameter_Init(&BALANCE_P,500,0,0,4,//60,0.5,-30,0,
						 //						  float max_error, float min_error,
						 //                          float alpha,
						 700, -700,
						 14000, -14000); // 平衡PID
	P_PID_Parameter_Init(&BALANCE_I,40,0,0,0,//60,0.5,-30,0,
						 //						  float max_error, float min_error,
						 //                          float alpha,
						 500, -500,
						 14000, -14000); // 平衡PID
	P_PID_Parameter_Init(&SPEED_P,-1.5,-0.3,0,7300,//-0.5  -0.15软
						 //						  float max_error, float min_error,
						 //                          float alpha,
						 3500, -3500,
						 10000, -10000); // 速度PID
		SPEED_P.max_error=30;
		SPEED_P.min_error=-30;

P_PID_V2_Init(&SPEED_P_v2,-2,-0.5,1.5,7300,//-0.5  -0.15软
						3000,-3000, //						  float max_error, float min_error,
						20,-20, //                          float alpha,
						 1500, -1500,
						 10000, -10000); // 速度PIDV2

	P_PID_Parameter_Init(&change_direction_angle,6,0,0,0,//-0.5  -0.15软
						 //						  float max_error, float min_error,
						 //                          float alpha,
						 0, -0,
						 300, -300); // 转向环角度PID
	P_PID_Parameter_Init(&change_direction_speed,90,0,0,7300,//-0.5  -0.15软
						 //						  float max_error, float min_error,
						 //                          float alpha,
						 2000, -2000,
						 6000, -6000); // 转向环速度PID
#endif
#if 0 // 第4代参数 软
	P_PID_Parameter_Init(&BALANCE_P,500,0,0,4,//60,0.5,-30,0,
						 //						  float max_error, float min_error,
						 //                          float alpha,
						 700, -700,
						 14000, -14000); // 平衡PID
	P_PID_Parameter_Init(&BALANCE_I,40,0,0,0,//60,0.5,-30,0,
						 //						  float max_error, float min_error,
						 //                          float alpha,
						 500, -500,
						 14000, -14000); // 平衡PID
	P_PID_Parameter_Init(&SPEED_P,-1.5,-0.1,0,7300,//-0.5  -0.15软
						 //						  float max_error, float min_error,
						 //                          float alpha,
						 3500, -3500,
						 10000, -10000); // 速度PID
		SPEED_P.max_error=30;
		SPEED_P.min_error=-30;

P_PID_V2_Init(&SPEED_P_v2,-1.5,-0.1,1,7300,//-0.5  -0.15软
						3000,-3000, //						  float max_error, float min_error,
						10,-10, //                          float alpha,
						 1500, -1500,
						 10000, -10000); // 速度PIDV2
P_PID_V2_Init(&POSITION_v2,-2,0,0,7300,//-0.5  -0.15软
						999,-999, //						  float max_error, float min_error,
						10,-10, //                          float alpha,
						 1500, -1500,
						 6666, -6666); // 速度PIDV2

	P_PID_Parameter_Init(&change_direction_angle,6,0,0,0,//-0.5  -0.15软
						 //						  float max_error, float min_error,
						 //                          float alpha,
						 0, -0,
						 555, -555); // 转向环角度PID
	P_PID_Parameter_Init(&change_direction_speed,90,0,0,7300,//-0.5  -0.15软
						 //						  float max_error, float min_error,
						 //                          float alpha,
						 2000, -2000,
						 6000, -6000); // 转向环速度PID
#endif
#if 0 // 第5代参数 软
	P_PID_Parameter_Init(&BALANCE_P,500,0,0,4,//60,0.5,-30,0,
						 //						  float max_error, float min_error,
						 //                          float alpha,
						 700, -700,
						 14000, -14000); // 平衡PID
	P_PID_Parameter_Init(&BALANCE_I,40,0,0,0,//60,0.5,-30,0,
						 //						  float max_error, float min_error,
						 //                          float alpha,
						 500, -500,
						 14000, -14000); // 平衡PID
	P_PID_Parameter_Init(&SPEED_P,-1.5,0,1.5,7300,//-0.5  -0.15软
						 //						  float max_error, float min_error,
						 //                          float alpha,
						 3500, -3500,
						 10000, -10000); // 速度PID
		SPEED_P.max_error=30;
		SPEED_P.min_error=-30;

P_PID_V2_Init(&SPEED_P_v2,-1.5,0,1.5,7300,//-0.5  -0.15软
						3000,-3000, //						  float max_error, float min_error,
						10,-10, //                          float alpha,
						 1500, -1500,
						 10000, -10000); // 速度PIDV2
P_PID_V2_Init(&POSITION_v2,-2,0,0,7300,//-0.5  -0.15软
						999,-999, //						  float max_error, float min_error,
						10,-10, //                          float alpha,
						 1500, -1500,
						 6666, -6666); // 速度PIDV2

	P_PID_Parameter_Init(&change_direction_angle,6,0,0,0,//-0.5  -0.15软
						 //						  float max_error, float min_error,
						 //                          float alpha,
						 0, -0,
						 700, -7700); // 转向环角度PID
	P_PID_Parameter_Init(&change_direction_speed,40,0,0,7300,//-0.5  -0.15软
						 //						  float max_error, float min_error,
						 //                          float alpha,
						 2000, -2000,
						 15000, -15000); // 转向环速度PID
#endif
#if 1											   // 第6代参数 关节电机使能
	P_PID_Parameter_Init(&BALANCE_P, 400, 0, 0, 4, // 60,0.5,-30,0,
												   //						  float max_error, float min_error,
												   //                           float alpha,
						 700, -700,
						 14000, -14000);		  // 平衡PID
	P_PID_Parameter_Init(&BALANCE_I, 60, 0, 0, 0, // 60,0.5,-30,0,
												  //						  float max_error, float min_error,
												  //                           float alpha,
						 500, -500,
						 14000, -14000);		   // 平衡PID
	P_PID_Parameter_Init(&SPEED_P, -1, 0, 2, 7300, //-0.5  -0.15软
												   //						  float max_error, float min_error,
												   //                          float alpha,
						 3500, -3500,
						 10000, -10000); // 速度PID
	SPEED_P.max_error = 30;
	SPEED_P.min_error = -30;

	P_PID_V2_Init(&SPEED_P_v2, -1.5, 0, 1.5, 7300, //-0.5  -0.15软
				  3000, -3000,					   //						  float max_error, float min_error,
				  10, -10,						   //                          float alpha,
				  1500, -1500,
				  10000, -10000);			   // 速度PIDV2
	P_PID_V2_Init(&POSITION_v2, 1, 0, 0, 7300, //-0.5  -0.15软
				  999, -999,				   //						  float max_error, float min_error,
				  10, -10,					   //                          float alpha,
				  1500, -1500,
				  6666, -6666); // 速度PIDV2

	P_PID_Parameter_Init(&change_direction_angle, 6, 0, 0, 0, //-0.5  -0.15软
															  //						  float max_error, float min_error,
															  //                          float alpha,
						 0, -0,
						 700, -7700);							  // 转向环角度PID
	P_PID_Parameter_Init(&change_direction_speed, 40, 0, 0, 7300, //-0.5  -0.15软
																  //						  float max_error, float min_error,
																  //                          float alpha,
						 2000, -2000,
						 15000, -15000);							// 转向环速度PID    MIT_change_focus
	P_PID_V2_Init(&MIT_change_focus_by_speed, 0.05, 0.01, 0, 19999, //-0.5  -0.15软
				  19999, -19999,									//						  float max_error, float min_error,
				  1, -1,											//                          float alpha,
				  30, -30,
				  25, -25);								 // 平衡-根据目标速度改变重心PID
	P_PID_V2_Init(&MIT_change_focus, 0.3, 0.5, 0, 19999, //-0.5  -0.15软
				  19999, -19999,						 //						  float max_error, float min_error,
				  1, -1,								 //                          float alpha,
				  500, -500,
				  5000, -5000); // 平衡-根据位置改变目标速度PID

#endif

	P_PID_Parameter_Init(&LQR_SPEED_BY_POSITION, -0.004, 0, 0, 7300, //-0.5  -0.15软
																	 //						  float max_error, float min_error,
																	 //                          float alpha,
						 2000, -2000,
						 3000, -3000); // 通过位置误差计算出LQR目标速度

	P_PID_Parameter_Init(&keep_BALENCE_by_MIT, 1, 0, 0, 20, //-0.5  -0.15软
															//						  float max_error, float min_error,
															//                          float alpha,
						 500, -500,
						 25, -25); //

	SPEED_L.LPF_K = 0.85;
	SPEED_R.LPF_K = 0.85;
	SPEED_R_FOR_MIT.LPF_K = 0.15;
	SPEED_L_FOR_MIT.LPF_K = 0.15;

	milemeter_A.LPF_K = 0.1;
	milemeter_test.K_LQR_use = 2;

	ZX.Rate = 1;
	ZX.Absolute_Max = 660;
	P_PID_Parameter_Init(&RC_SPEED_TO_POSITION, 0.8, 0, 0, 0, //-0.00001
															  //						  float max_error, float min_error,
															  //                          float alpha,
						 0, -0,
						 160000, -160000); // //位置环（输入目标位置,得到倾斜角度）

	P_PID_Parameter_Init(&POSITION, 0, 0, 0, 0, //-0.00001
												//						  float max_error, float min_error,
												//                          float alpha,
						 0, -0,
						 12, -12); // //位置环（输入目标位置,得到倾斜角度）

	P_PID_Parameter_Init(&MIT_TEXT, 25, 0.3, 0, 100, //-0.00001
													 //						  float max_error, float min_error,
													 //                          float alpha,
						 10, -10,
						 35, -35);							  // //MIT电机  角度环得到速度
	P_PID_Parameter_Init(&MIT_SPEED_TEXT, 0.8, 0.03, -0.6, 4, //-0.00001
						 //						  float max_error, float min_error,
						 //                          float alpha,
						 555, -555,
						 80, -80);							 // //MIT电机 速度环
	P_PID_Parameter_Init(&MIT_POSITION_TEXT, 1, 0.1, 0, 100, //-0.00001
						 //						  float max_error, float min_error,
						 //                          float alpha,
						 500, -500,
						 80, -80); // //MIT电机 位置环
	P_PID_Parameter_Init(&keep_ROW_BALENCE, -1.5, -0.01, 1, 10, //-0.00001
						 //						  float max_error, float min_error,
						 //                          float alpha,
						 150, -150,
						 10, -10); // //MIT电机 位置环
	P_PID_Parameter_Init(&MF9025_SPEED,1.0, 0.15, 0,4000, //-0.00001
						 //						  float max_error, float min_error,
						 //                          float alpha,
						 2000, -2000,
						 2000, -2000); // //MIT电机 位置环
	MIT_PID_INIT();
	SPEED_MIT_A.LPF_K = 0.04;
	SPEED_MIT_B.LPF_K = 0.04;
	SPEED_MIT_C.LPF_K = 0.04;
	SPEED_MIT_D.LPF_K = 0.04;

	SPEED_MIT.LPF_K = 0.04;

	CHASSIS_follow_xp.Absolute_Max=180;
	CHASSIS_follow_xp.Rate=0.3;
	// Vision_Control_Init();//卡尔曼参数初始化   TIRE_L_SPEED_pid   BALANCE_I

	/* USER CODE END Init */

	/* USER CODE BEGIN RTOS_MUTEX */
	/* add mutexes, ... */

	CAN1_Config();
	//	CAN1_Filter0_Init();
	//
	//	__HAL_CAN_ENABLE_IT(&hcan1, CAN_IT_RX_FIFO0_MSG_PENDING);

	//	HAL_CAN_Start(&hcan1);

	CAN2_Config();
//	// 视觉
//	__HAL_UART_CLEAR_IDLEFLAG(&huart6);

//	__HAL_UART_ENABLE_IT(&huart6, UART_IT_IDLE);

//	USART_RX_DMA_ENABLE(&huart6, Vision_DataBuff, Vision_BuffSize);
//	ext_robot_hurt.data.hurt_type = 10; // 避免初始值为0误识别

	//裁判系统
	__HAL_UART_CLEAR_IDLEFLAG(&huart6);

	__HAL_UART_ENABLE_IT(&huart6, UART_IT_IDLE);

	USART_RX_DMA_ENABLE(&huart6, JudgeSystem_rxBuff, JUDGESYSTEM_PACKSIZE);

	// DJIC_IMU.pitch_turnCounts=-1;
	// CAN2_Filter0 初始化 使能
	//	  HAL_Delay(1000);

	//	CAN2_Filter0_Init();
	//

	//	__HAL_CAN_ENABLE_IT(&hcan2, CAN_IT_RX_FIFO0_MSG_PENDING);

	//			HAL_CAN_Start(&hcan2);

	/* USER CODE END RTOS_MUTEX */

	/* USER CODE BEGIN RTOS_QUEUES */
	/* add queues, ... */
	CAN2_Queue = xQueueCreate(64, sizeof(CAN_Rx_TypeDef));
	CAN1_Queue = xQueueCreate(32, sizeof(CAN_Rx_TypeDef));
	MX_USB_DEVICE_Init();

	/* USER CODE END RTOS_QUEUES */

	/* Create the thread(s) */
	/* definition and creation of test */
	osThreadDef(test, test_task, osPriorityNormal, 0, 128);
	testHandle = osThreadCreate(osThread(test), NULL);

	/* definition and creation of Debug_Task */
	osThreadDef(Debug_Task, Debug, osPriorityNormal, 0, 128);
	Debug_TaskHandle = osThreadCreate(osThread(Debug_Task), NULL);

	/* definition and creation of IMU_Send_Task */
	osThreadDef(IMU_Send_Task, IMU_Send, osPriorityHigh, 0, 128);
	IMU_Send_TaskHandle = osThreadCreate(osThread(IMU_Send_Task), NULL);

	/* definition and creation of Can2_Rei_Task */
	osThreadDef(Can2_Rei_Task, Can2_Reivece, osPriorityAboveNormal, 0, 128);
	Can2_Rei_TaskHandle = osThreadCreate(osThread(Can2_Rei_Task), NULL);

	/* definition and creation of CAN1 */
	osThreadDef(CAN1, CAN1_R, osPriorityAboveNormal, 0, 128);
	CAN1Handle = osThreadCreate(osThread(CAN1), NULL);

	/* USER CODE BEGIN RTOS_THREADS */
	/* add threads, ... */
	osThreadDef(cali, calibrate_task, osPriorityAboveNormal, 0, 512);
	calibrate_tast_handle = osThreadCreate(osThread(cali), NULL);

	osThreadDef(imuTask, INS_task, osPriorityRealtime, 0, 1024);
	imuTaskHandle = osThreadCreate(osThread(imuTask), NULL);

	osThreadDef(led, led_RGB_flow_task, osPriorityNormal, 0, 256);
	led_RGB_flow_handle = osThreadCreate(osThread(led), NULL);

	//	  osDelay(3000);
	//	  osDelay(3000);
	//	  osDelay(3000);

	osThreadDef(Task_Robot_Control, Robot_Control, RobotCtrl_Priority, 0, RobotCtrl_Size);
	RobotCtrl_Handle = osThreadCreate(osThread(Task_Robot_Control), NULL);
	PITCH_trage_angle = DJIC_IMU.total_pitch;

	//

	/* USER CODE END RTOS_THREADS */
}

__weak void test_task(void const *argument)
{
	/* init code for USB_DEVICE */
	MX_USB_DEVICE_Init();
	for (;;)
	{
		osDelay(1);
	}
}

/* USER CODE BEGIN Header_Debug */
/**
 * @brief Function implementing the Debug_Task thread.
 * @param argument: Not used
 * @retval None
 */
// fp32 voltage;
uint8_t text_send[5];
char text_e[5] = "A432B";
#ifdef FREERTOS_TASK_TIME

		char RunTimeInfo[400];		//保存任务运行时间信息
#endif

/* USER CODE END Header_Debug */
void Debug(void const *argument)
{
	/* USER CODE BEGIN Debug */
	int debug_times = 0;
	char error_e[5] = "error";

	uint16_t range_i = 0;
	uint16_t give_i = 0;

	/*
		char RunTimeInfo[400];		//保存任务运行时间信息

	char RunTimeInfo[400];		//保存任务运行时间信息
	任务名\t\t\t运行时间\t运行所占百分比
	Debug_Task     	427		<1%     反馈给上位机
	led            	5866		<1%      led
	IDLE           	398036		58%  空闲
	IMU_Send_Task  	117005		17%  发给视觉
	cali           	63268		9%    校准
	test           	455		<1%       什么都没做
	Task_Robot_Cont	31306		4%    总控制
	Can2_Rei_Task  	463		<1%       CAN2接收
	imuTask        	13982		2%    陀螺仪任务
	CAN1           	49718		7%    CAN1接收
	Tmr Svc        	0		<1%

	任务名\t\t\t运行时间\t运行所占百分比
	Debug_Task     	4706		<1%
	IDLE           	720445		27%
	IMU_Send_Task  	1436986		54%
	cali           	127828		4%
	led            	4709		<1%
	test           	457		<1%
	Task_Robot_Cont	285106		10%
	Tmr Svc        	0		<1%
	imuTask        	50511		1%
	Can2_Rei_Task  	1		<1%
	CAN1           	0		<1%

	Debug_Task     	5814		<1%
	led            	5804		<1%
	IDLE           	885108		27%
	IMU_Send_Task  	1764361		54%
	cali           	157311		4%
	test           	554		<1%
	Task_Robot_Cont	350312		10%
	Tmr Svc        	0		<1%
	imuTask        	62044		1%
	Can2_Rei_Task  	1		<1%
	CAN1           	0		<1%

			*/
	//		buzzer_control.work = TRUE;
	/* Infinite loop */
	for (;;)
	{
		debug_times++;
		Get_FPS(&FPS_ALL.DEBUG.WorldTimes, &FPS_ALL.DEBUG.FPS);
				if (debug_times % 10 == 0) // 永久失能检测
				{
				if (DR16.rc.s_left == 2&&DR16.rc.ch3<-600) //失能保护
				{
					disable_for_test=1;
				}
				if (DR16.rc.s_left == 2&&DR16.rc.ch3>-100) //失能保护
				{
					disable_for_test=0;
				}
				}
		if (debug_times % 2 == 0) // 上位机发送频率
		{
			NM_swj();

			// 2ms一次
			//			printf("好");
		}
		if (DR16.rc.s_right != 2 && DR16.rc.s_right != 0) // 是否上位机
		{

			//					USART1->DR = '2';
			//					TRY[0]='0';
			//										TRY[1]='1';

			//	HAL_UART_Transmit_DMA(&huart1,&TRY[0],2);
			if (cali_sensor[0].cali_done == CALIED_FLAG && cali_sensor[0].cali_cmd == 0)
			{
			}
			//
		}

		if (debug_times % 100 == 0) // 上位机发送频率
		{
			range_i++;
			if (range_i == 1)
			{
				text_e[0] = 'a';
				text_e[1] = '9';
				text_e[2] = '8';
				text_e[3] = '7';
				text_e[4] = 'b';
			}
			if (range_i == 2)
			{
				text_e[0] = 'c';
				text_e[1] = '1';
				text_e[2] = '2';
				text_e[3] = '3';
				text_e[4] = 'd';
				range_i = 0;
			}
			for (give_i = 0; give_i < 5; give_i++)
			{
				text_send[give_i] = (char)(text_e[give_i]);
			}

			//			CDC_Transmit_FS(&text_send[0],5);
		}

		if (DR16.rc.s_left == 1)
		{
			if (in_END == 1 && in_END_last == 0) // 上一时刻不在轨道末端,这一时刻在轨道末端
			{
				stay_in_track_end_times++; // 1ms增加一次
			}
			if (stay_in_track_end_times > 0)
			{
				stay_in_track_end_times++;
			}
			if (stay_in_track_end_times > 1600)
			{
				stay_in_track_end_times = 0;
			}
			if (in_END == 0)
			{
				stay_in_track_end_times = 0; // 这一时刻不在轨道末端了,那肯定就不需要计时了,计时清零
			}
		}
		in_END_last = in_END;
		if (debug_times % 100 == 0) // 100ms运行一次

		{
			// get battery voltage
			// 获取电源电压

			//        my_voltage = get_battery_voltage();
			if (my_voltage < 21 && my_voltage > 20)
			{
				if (debug_times % 5000 == 0) // 5s运行一次
				{
					Buzzer.mode = One_times;
				}
			}
		}
		if (debug_times % 1000 == 0) // 1s运行一次
		{
			//		    oled_clear(Pen_Clear);
			// oled_printf(1,1,error_e);
			//	    oled_refresh_gram();
		}

#ifdef FREERTOS_TASK_TIME
		if (debug_times % 1000 == 0) // 1s运行一次
		{
			memset(RunTimeInfo, 0, 400); // 信息缓冲区清零

			vTaskGetRunTimeStats(RunTimeInfo); // 获取任务运行时间信息
			HAL_UART_Transmit_DMA(&huart1, (uint8_t *)&RunTimeInfo, 400);
		}
#endif

		// BEEP_TEXT();

		laoliu_gjiwo_times_ago++; // 老六攻击我
		hurt_times_ago++;
		if (ext_robot_hurt.data.hurt_type == 0)
		{
			if (ext_robot_hurt.data.armor_id == 0 || ext_robot_hurt.data.armor_id == 1)
			{
				hurt_times_ago = 0; // 被击中了

				if (ext_robot_hurt.data.armor_id == 1) // 背面装甲板受击
				{
					laoliu_gjiwo_times_ago = 0; // 老六攻击我
				}
				ext_robot_hurt.data.hurt_type = 10;
			}
		}
		osDelay(1);
	}
	/* USER CODE END Debug */
}

/* USER CODE BEGIN Header_IMU_Send */
int MIT_A_FPS_1000ms;
int MIT_B_FPS_1000ms;
int MIT_C_FPS_1000ms;
int MIT_D_FPS_1000ms;
int run_times_for_fps;

/**
 * @brief Function implementing the IMU_Send_Task thread.
 * @param argument: Not used
 * @retval None
 */
/* USER CODE END Header_IMU_Send */
void IMU_Send(void const *argument)
{
	/* USER CODE BEGIN IMU_Send */
	portTickType xLastWakeTime;
	xLastWakeTime = xTaskGetTickCount();
	const TickType_t TimeIncrement = pdMS_TO_TICKS(2); // 每十毫秒强制进入总控制

	/* Infinite loop */
	for (;;)
	{
		run_times_for_fps++;
#if send_way == 0

#endif
		if(run_times_for_fps>=500)
		{
			MIT_A_FPS_1000ms=MIT_A.RC_TIMES;
			MIT_A.RC_TIMES=0;
			MIT_B_FPS_1000ms=MIT_B.RC_TIMES;
			MIT_B.RC_TIMES=0;
			MIT_C_FPS_1000ms=MIT_C.RC_TIMES;
			MIT_C.RC_TIMES=0;
			MIT_D_FPS_1000ms=MIT_D.RC_TIMES;
			MIT_D.RC_TIMES=0;
		run_times_for_fps=0;

		}
				if (send_to_C == 1)//遥控器数据
		{
DR16_send_master_control();
						send_to_C = 0;
			send_to_C_times++;
		}
		if(send_to_C_JS_HURT==1)//伤害状态数据，伤害发生后发送
		{
			send_to_C_JS_HURT=0;
			JS_send_HURT_control();
		}
		if (send_to_C_JS_SHOOT == 1)//实时射击数据，子弹发射后发送
		{
JS_send_SHOOT_control();
			JS_SEND_times++;
			send_to_C_JS_SHOOT=0;
		}
		if (send_to_C_JS_STATUS == 1)//裁判系统_状态数据_10Hz 周期发送
		{
			send_to_C_STATUS_times++;
JS_send_STATUS_control();
			send_to_C_JS_STATUS=0;
		}
		if(send_to_C_JS_HEAT == 1)
		{
			JS_send_HEAT_control();
			send_to_C_JS_HEAT=0;
		}

		if (DR16.rc.s_left == 2)
		{
			if (DR16.rc.ch0 < -600 && DR16.rc.ch1 < -600 && DR16.rc.ch3 < -600 && DR16.rc.ch2 > 600)//内八

			{
				calibration_times++;
			}
			else
			{
				calibration_times = 0;
			}
			if (DR16.rc.ch0 > 600 && DR16.rc.ch1 > 600 && DR16.rc.ch3 > 600 && DR16.rc.ch2 < -600)//再外八
			{
				flash_read_times++;
			}
			else
			{
				flash_read_times = 0;
			}

			if (flash_read_times > 500)
			{
				flash_read_times = -10000;
				MIT_init_angle_read_from_flash();
				Buzzer.mode = One_times;
			}

			if (calibration_times > 500)
			{
				// MIT_calibration();
				//	MIT_init_angle_read_from_flash();
				MIT_init_angle_WRITE_to_flash();
				calibration_times = -10000;
				Buzzer.mode = One_times;

				if (MIT_MODE_TEXT != 2) // 还没有失能电机//校准时还有强制失能的作用
				{
					DISABLE_ALL_MIT(); // 失能所有电机
					MIT_MODE_TEXT = 2; // 电机失能
				}
			}
		}

		vTaskDelayUntil(&xLastWakeTime, TimeIncrement);
	}
	/* USER CODE END IMU_Send */
}

void Can2_Reivece(void const *argument)
{
	/* USER CODE BEGIN Can2_Reivece */
	/* Infinite loop */
	/* USER CODE BEGIN Can2_Reivece */
	// CAN2接收队列发送的数据的结构体变量
	CAN_Rx_TypeDef CAN2_Rx_Structure;
	// 出队的状态变量
	BaseType_t ExitQueue_Status;
	int i = 0;
	int speed_i = 0;

	/* Infinite loop */
	for (;;)
	{
		// 死等队列有消息
		ExitQueue_Status = xQueueReceive(CAN2_Queue, &CAN2_Rx_Structure, portMAX_DELAY);
		// 出队成功
		if (ExitQueue_Status == pdTRUE)
		{
			CAN2_rc_times++;
			can2_DR16_TIMES++;
						if (CAN2_Rx_Structure.CAN_RxMessage.StdId == YAW_6020_SEND_ID)
			{
				// 云台
				GM6020_Yaw_getInfo(CAN2_Rx_Structure);
				Get_FPS(&FPS_ALL.YAW_6020.WorldTimes, &FPS_ALL.YAW_6020.FPS);

			}
			// 陀螺仪校准指令
			//			if (CAN2_Rx_Structure.CAN_RxMessage.StdId == IMU_CAL_REIID)
			//			{
			//				//解包
			//				IMU_Cal_Status_Reivece(CAN2_Rx_Structure);
			//			}
	}
	}
	//    osDelay(1);
	/* USER CODE END Can2_Reivece */
}

void CAN1_R(void const *argument)
{
	/* USER CODE BEGIN CAN1_R */
	// CAN1接收队列发送的数据的结构体变量
	CAN_Rx_TypeDef CAN1_Rx_Structure;

	// 出队的状态变量
	BaseType_t ExitQueue_Status;
	/* Infinite loop */
	for (;;)
	{
		// 死等队列有消息
		ExitQueue_Status = xQueueReceive(CAN1_Queue, &CAN1_Rx_Structure, portMAX_DELAY);
		// 出队成功

		if (ExitQueue_Status == pdTRUE)
		{
			if (CAN1_Rx_Structure.CAN_RxMessage.StdId == MF9025_READID_START)
			{
				// 左摩擦轮的    ID1
				MF9025_getInfo(CAN1_Rx_Structure); //
				Get_FPS(&FPS_ALL.L_9025.WorldTimes, &FPS_ALL.L_9025.FPS);

			}
			if (CAN1_Rx_Structure.CAN_RxMessage.StdId == (M3508_READID_START + 3))
			{
				// 左摩擦轮的    ID1
				M3508_getInfo(CAN1_Rx_Structure); //
				Get_FPS(&FPS_ALL.R_3508.WorldTimes, &FPS_ALL.R_3508.FPS);

			}
			if (CAN1_Rx_Structure.CAN_RxMessage.StdId == (M3508_READID_START + 2))
			{
				// 右摩擦轮的	ID2
				M3508_getInfo(CAN1_Rx_Structure); //
				Get_FPS(&FPS_ALL.L_3508.WorldTimes, &FPS_ALL.L_3508.FPS);

			}
			if (CAN1_Rx_Structure.CAN_RxMessage.StdId == (M3508_READID_START + 1))
			{
				// 拨盘电机		ID3
				M2006_getInfo(CAN1_Rx_Structure); //
			}

//			if (CAN1_Rx_Structure.CAN_RxMessage.StdId == GM6020_READID_START)
//			{
//				// 云台
//				GM6020_Yaw_getInfo(CAN1_Rx_Structure);
//			}

//			if (CAN1_Rx_Structure.CAN_RxMessage.StdId == (GM6020_READID_START + 1))
//			{
//				// 云台的yaw轴
//				GM6020_Pitch_getInfo(CAN1_Rx_Structure); // 6400-7160
//			}

//			if (CAN1_Rx_Structure.CAN_RxMessage.StdId == GM6020_READID_START + 2)
//			{
//				// 云台
//				GM6020_Yaw_getInfo(CAN1_Rx_Structure);
//			}

//			if (CAN1_Rx_Structure.CAN_RxMessage.StdId == GM6020_READID_END)
//			{
//				// 云台的pitch轴3743-4557
//				GM6020_Pitch_getInfo(CAN1_Rx_Structure); // 6400-7160
//			}

						if (CAN1_Rx_Structure.CAN_RxMessage.StdId == TEST_MIT_MASTER_ID)
			{
				MIT_RC_TIMES++;
				if (CAN1_Rx_Structure.CAN_RxMessageData[0] == TEST_MIT_SLAVE_ID)
				{
					for (int x = 0; x < 6; x++)
					{
						text_moto.MIT_RAW_DATA[x] = CAN1_Rx_Structure.CAN_RxMessageData[x];
					}
					text_moto.position = (CAN1_Rx_Structure.CAN_RxMessageData[2] | CAN1_Rx_Structure.CAN_RxMessageData[1] << 8);

					text_moto.velocity =
						(((CAN1_Rx_Structure.CAN_RxMessageData[4]) >> 4) |
						 (CAN1_Rx_Structure.CAN_RxMessageData[3]) << 4);

					text_moto.current = (CAN1_Rx_Structure.CAN_RxMessageData[5] | (CAN1_Rx_Structure.CAN_RxMessageData[4] & 0xF) << 8);

					text_moto.position_end = uint_to_float(text_moto.position, P_MIN, P_MAX, 16);
					text_moto.ANGLE_JD = text_moto.position_end * Angle_turn_Radian;
					// speed_i++;
					// MIT_SPEED_BY_ANGLE_TEMP+=(text_moto.position-MIT_ANGLE_JD_LAST);
					//			MIT_ANGLE_JD_LAST_LAST=MIT_ANGLE_JD_LAST;
					// MIT_ANGLE_JD_LAST=	text_moto.position;
					//
					//			if(speed_i>i_for_speed)
					//			{
					//				MIT_SPEED_BY_ANGLE=MIT_SPEED_BY_ANGLE_TEMP;
					//				MIT_SPEED_BY_ANGLE_TEMP=0;
					//				speed_i=0;
					//			}
					MIT_SPEED_NEW = LPF_V2(&SPEED_MIT, text_moto.velocity) + 5;

					text_moto.velocity_end = uint_to_float(MIT_SPEED_NEW, V_MIN, V_MAX, 12);
					text_moto.SPEED_JD = text_moto.velocity_end * Angle_turn_Radian;

					text_moto.current_end = uint_to_float(text_moto.current, T_MIN, T_MAX, 12);

					MIT_RC_Process_TIMES++;
				}
			}
			if (CAN1_Rx_Structure.CAN_RxMessage.StdId == MIT_A_MASTER_ID)
			{
				if (CAN1_Rx_Structure.CAN_RxMessageData[0] == MIT_A_SLAVE_ID)
				{
					Get_FPS(&FPS_ALL.MIT_A.WorldTimes, &FPS_ALL.MIT_A.FPS);

					for (int x = 0; x < 6; x++)
					{
						MIT_A.MIT_RAW_DATA[x] = CAN1_Rx_Structure.CAN_RxMessageData[x];
					}
					MIT_A.position = (CAN1_Rx_Structure.CAN_RxMessageData[2] | CAN1_Rx_Structure.CAN_RxMessageData[1] << 8);
					//
					MIT_A.velocity =
						(((CAN1_Rx_Structure.CAN_RxMessageData[4]) >> 4) |
						 (CAN1_Rx_Structure.CAN_RxMessageData[3]) << 4);

					MIT_A.current = (CAN1_Rx_Structure.CAN_RxMessageData[5] | (CAN1_Rx_Structure.CAN_RxMessageData[4] & 0xF) << 8);

					MIT_A.position_end = uint_to_float(MIT_A.position, P_MIN, P_MAX, 16);
					MIT_A.ANGLE_JD = MIT_A.position_end * Angle_turn_Radian;

					MIT_A.MIT_SPEED_TEMP = LPF_V2(&SPEED_MIT_A, MIT_A.velocity) + 5;

					MIT_A.velocity_end = uint_to_float(MIT_A.MIT_SPEED_TEMP, V_MIN, V_MAX, 12);
					MIT_A.SPEED_JD = MIT_A.velocity_end * Angle_turn_Radian;

					MIT_A.current_end = uint_to_float(MIT_A.current, T_MIN, T_MAX, 12);
				}
				MIT_A.RC_TIMES++;
			}

			if (CAN1_Rx_Structure.CAN_RxMessage.StdId == MIT_B_MASTER_ID)
			{
				if (CAN1_Rx_Structure.CAN_RxMessageData[0] == MIT_B_SLAVE_ID)
				{
					Get_FPS(&FPS_ALL.MIT_B.WorldTimes, &FPS_ALL.MIT_B.FPS);

					for (int x = 0; x < 6; x++)
					{
						MIT_B.MIT_RAW_DATA[x] = CAN1_Rx_Structure.CAN_RxMessageData[x];
					}
					MIT_B.position = (CAN1_Rx_Structure.CAN_RxMessageData[2] | CAN1_Rx_Structure.CAN_RxMessageData[1] << 8);

					MIT_B.velocity =
						(((CAN1_Rx_Structure.CAN_RxMessageData[4]) >> 4) |
						 (CAN1_Rx_Structure.CAN_RxMessageData[3]) << 4);

					MIT_B.current = (CAN1_Rx_Structure.CAN_RxMessageData[5] | (CAN1_Rx_Structure.CAN_RxMessageData[4] & 0xF) << 8);

					MIT_B.position_end = uint_to_float(MIT_B.position, P_MIN, P_MAX, 16);
					MIT_B.ANGLE_JD = MIT_B.position_end * Angle_turn_Radian;

					MIT_B.MIT_SPEED_TEMP = LPF_V2(&SPEED_MIT_B, MIT_B.velocity) + 5;

					MIT_B.velocity_end = uint_to_float(MIT_B.MIT_SPEED_TEMP, V_MIN, V_MAX, 12);
					MIT_B.SPEED_JD = MIT_B.velocity_end * Angle_turn_Radian;

					MIT_B.current_end = uint_to_float(MIT_B.current, T_MIN, T_MAX, 12);
				}
				MIT_B.RC_TIMES++;
			}

			if (CAN1_Rx_Structure.CAN_RxMessage.StdId == MIT_C_MASTER_ID)
			{
				if (CAN1_Rx_Structure.CAN_RxMessageData[0] == MIT_C_SLAVE_ID)
				{
					Get_FPS(&FPS_ALL.MIT_C.WorldTimes, &FPS_ALL.MIT_C.FPS);

					for (int x = 0; x < 6; x++)
					{
						MIT_C.MIT_RAW_DATA[x] = CAN1_Rx_Structure.CAN_RxMessageData[x];
					}
					MIT_C.position = (CAN1_Rx_Structure.CAN_RxMessageData[2] | CAN1_Rx_Structure.CAN_RxMessageData[1] << 8);

					MIT_C.velocity =
						(((CAN1_Rx_Structure.CAN_RxMessageData[4]) >> 4) |
						 (CAN1_Rx_Structure.CAN_RxMessageData[3]) << 4);

					MIT_C.current = (CAN1_Rx_Structure.CAN_RxMessageData[5] | (CAN1_Rx_Structure.CAN_RxMessageData[4] & 0xF) << 8);

					MIT_C.position_end = uint_to_float(MIT_C.position, P_MIN, P_MAX, 16);
					MIT_C.ANGLE_JD = MIT_C.position_end * Angle_turn_Radian;

					MIT_C.MIT_SPEED_TEMP = LPF_V2(&SPEED_MIT_C, MIT_C.velocity) + 5;

					MIT_C.velocity_end = uint_to_float(MIT_C.MIT_SPEED_TEMP, V_MIN, V_MAX, 12);
					MIT_C.SPEED_JD = MIT_C.velocity_end * Angle_turn_Radian;

					MIT_C.current_end = uint_to_float(MIT_C.current, T_MIN, T_MAX, 12);
				}
				MIT_C.RC_TIMES++;
			}
			if (CAN1_Rx_Structure.CAN_RxMessage.StdId == MIT_D_MASTER_ID)
			{
				if (CAN1_Rx_Structure.CAN_RxMessageData[0] == MIT_D_SLAVE_ID)
				{
					Get_FPS(&FPS_ALL.MIT_D.WorldTimes, &FPS_ALL.MIT_D.FPS);

					for (int x = 0; x < 6; x++)
					{
						MIT_D.MIT_RAW_DATA[x] = CAN1_Rx_Structure.CAN_RxMessageData[x];
					}
					MIT_D.position = (CAN1_Rx_Structure.CAN_RxMessageData[2] | CAN1_Rx_Structure.CAN_RxMessageData[1] << 8);

					MIT_D.velocity =
						(((CAN1_Rx_Structure.CAN_RxMessageData[4]) >> 4) |
						 (CAN1_Rx_Structure.CAN_RxMessageData[3]) << 4);

					MIT_D.current = (CAN1_Rx_Structure.CAN_RxMessageData[5] | (CAN1_Rx_Structure.CAN_RxMessageData[4] & 0xF) << 8);

					MIT_D.position_end = uint_to_float(MIT_D.position, P_MIN, P_MAX, 16);
					MIT_D.ANGLE_JD = MIT_D.position_end * Angle_turn_Radian;

					MIT_D.MIT_SPEED_TEMP = LPF_V2(&SPEED_MIT_D, MIT_D.velocity) + 5;

					MIT_D.velocity_end = uint_to_float(MIT_D.MIT_SPEED_TEMP, V_MIN, V_MAX, 12);
					MIT_D.SPEED_JD = MIT_D.velocity_end * Angle_turn_Radian;

					MIT_D.current_end = uint_to_float(MIT_D.current, T_MIN, T_MAX, 12);
				}
				MIT_D.RC_TIMES++;
			}

		}
	}
	/* USER CODE END CAN1_R */
}

/* USER CODE BEGIN Application */
uint8_t TRY[20]; // 匿名上位机发送数据

int Driver_add = 32768;
int Robot_Control_times = 0;

void Robot_Control(void const *argument)
{
	/* USER CODE BEGIN RobotControl */
	portTickType xLastWakeTime;
	xLastWakeTime = xTaskGetTickCount();
	const TickType_t TimeIncrement = pdMS_TO_TICKS(1); // 每1毫秒强制进入总控制

	vTaskDelay(1000);
	vTaskDelay(1000);

//	vTaskDelay(1000);
//	vTaskDelay(1000);
	MIT_init_angle_read_from_flash();
	Buzzer.mode = Three_times;
R_Y=14.5;
R_X=10;

	/* Infinite loop */
	for (;;)
	{

		//		GM6020_SetVoltage(send_to_yaw,0 , 0, send_to_pitch); //云台  send_to_pitch
		//		GM6020_SetVoltage(0,0 , 0, 0); //云台  send_to_pitch
		keyBoard_WASD();//键鼠控制
		balance_control();//PID
		LQR_TEST_CON();//LQR

		if (send_to_tire_L > 15000)
			send_to_tire_L = 15000;
		if (send_to_tire_L < -15000)
			send_to_tire_L = -15000;
		if (send_to_tire_R > 15000)
			send_to_tire_R = 15000;
		if (send_to_tire_R < -15000)
			send_to_tire_R = -15000;

if (DR16.rc.s_left == 2)
{
send_to_tire_R = 0;
send_to_tire_L = 0;
}
if(disable_for_test==1)//disable_for_test如果等于1 那就不会使能轮电机
{
send_to_tire_R = 0;
send_to_tire_L = 0;
}
		/*轮胎电机*/ M3508s1_setCurrent(0, 0, send_to_tire_R, send_to_tire_L); // send_to_SHOOT_L阻力大
		// CAN2_SEND_TO_MIT();
		//		M3508s1_setCurrent(0, send_to_2006, send_to_SHOOT_R, send_to_SHOOT_L);//send_to_SHOOT_L阻力大

		if (DR16.rc.s_left == 2)
		{
			// MIT_MODE(MIT_MODE_TEXT);
			//	MIT_A_SPEED.Min_result=MIT_A_SPEED.Max_result=0;
			//	MIT_B_SPEED.Min_result=MIT_B_SPEED.Max_result=0;
			//	MIT_C_SPEED.Min_result=MIT_C_SPEED.Max_result=0;
			//	MIT_D_SPEED.Min_result=MIT_D_SPEED.Max_result=0;
			if (send_to_MIT_damping < 0.8f)
			{
				if (MIT_MODE_TEXT != 2) // 还没有失能电机
				{
					MIT_MODE_TEXT = 2; // 电机失能
				}
				DISABLE_ALL_MIT(); // 失能所有电机  至少运行两遍以上
			}
			else
			{
				send_to_MIT_damping -= 0.0005; // 2秒失能
//				if (liftoff_R > 3)
//				{
//					liftoff_R -= 0.01; // 将电机归位到起始点附近 一秒10度
//				}
				MIT_controul(); // 系数衰减的同时,继续控制电机

				//			SEND_TO_MIT_MAX.Target_Value=0;
				//			MAX_OUT=Ramp_Function(&SEND_TO_MIT_MAX);
			}
			//	if(MIT_B.ANGLE_JD<30)liftoff_R=75;
			//	else
			//		liftoff_R=15;
			position_text_TEMP = -1; // 重置目标位置
			position_text = -1;		 // 重置目标位置
			target_position_text_PID = text_moto.ANGLE_JD;
			MIT_DISABLE_TIMES++;
		}
		if (DR16.rc.s_left == 3 || DR16.rc.s_left == 1)
		{
			//	SEND_TO_MIT_MAX.Target_Value=70;
			//	MAX_OUT=Ramp_Function(&SEND_TO_MIT_MAX);
			if (send_to_MIT_damping < 1.0f)
			{
				send_to_MIT_damping += 0.0005; // 两秒启动
				liftoff_R = 10;				   // 将电机归位到起始点附近
			}

			if (MIT_MODE_TEXT != 1)
			{
				//		MIT_MODE(MIT_MODE_TEXT);//使能电机
				{
					if(disable_for_test==0)//disable_for_test如果等于1 那就不会使能关节电机
					{
					ALL_MIT_ENTER_MOTO_MODE(); // 使能所有电机
					}
					run_MIT_ENTER_MOTO_MODE_times++;
					if (run_MIT_ENTER_MOTO_MODE_times > 1)//1 2
					{
						run_MIT_ENTER_MOTO_MODE_times = 0;
						MIT_MODE_TEXT = 1;
					}
				}
			}
			else
			{
				MIT_controul();
			}
			MIT_ENABLE_TIMES = MIT_ENABLE_TIMES + 1;
		}
		/*
		if(DR16.rc.s_left==1)
		{
			if(sendto_MIT_TEXT==1)
					{
				MIT_MODE(MIT_MODE_TEXT);
					sendto_MIT_TEXT=0;
				}

		}*/
		// 关节电机测试模式

		//	mit_math_temp();//正解验算

		mit_math_temp(MIT_A.ANGLE_JD - MIT_A.MIT_TZG - 29.54,
					  MIT_B.MIT_TZG - MIT_B.ANGLE_JD - 29.54,
					  &R_C_X_NOW, &R_C_Y_NOW); // 正解验算 得到  R_C_Y_NOW  R_C_X_NOW
		mit_math_temp(MIT_C.ANGLE_JD - MIT_C.MIT_TZG - 29.54,
					  MIT_D.MIT_TZG - MIT_D.ANGLE_JD - 29.54,
					  &L_C_X_NOW, &L_C_Y_NOW); // 正解验算 得到  L_C_Y_NOW  L_C_X_NOW
		real_engine_body_height=(R_C_Y_NOW+L_C_Y_NOW)/2;

		//MIT_C.ANGLE_JD 20
		swing_link_length_L=sqrt((L_C_X_NOW-10.0)*(L_C_X_NOW-10.0)+L_C_Y_NOW*L_C_Y_NOW);
		//求摆杆长度 实时计算LQR参数要用到

		swing_link_length=sqrt((R_C_X_NOW-10.0)*(R_C_X_NOW-10.0)+R_C_Y_NOW*R_C_Y_NOW);
		//求摆杆长度 实时计算LQR参数要用到
		swing_link_length_R=swing_link_length;

		Robot_Control_times++;
		if(Robot_Control_times%4==0)
		{
//		MIT_orque_TG();
		}
		update_gyro(); // 由角度计算角速度
//		gyro_test();   // 积分角速度比较速度验证
		speed_accel();
		mf9025_tgg_speed=DR16.rc.ch1*1.0/660.0*4000;
		P_PID_bate(&MF9025_SPEED,mf9025_tgg_speed,MF9025[0].realSpeed);
		send_to_MF9025_TEST=MF9025_SPEED.result;
		if (DR16.rc.s_left == 2||DR16.rc.s_left == 0)
		{
		send_to_MF9025_TEST=0;
			mf9025_tgg_speed=0;
		}

		if(send_to_MF9025_TEST>2000)
		{send_to_MF9025_TEST=2000;}
		if(send_to_MF9025_TEST<-2000)
		{send_to_MF9025_TEST=-2000;}
MF9025_setTorque(send_to_MF9025_TEST,0,0,0);

		vTaskDelayUntil(&xLastWakeTime, TimeIncrement);
	}

	/* USER CODE END RobotControl */
}
/* USER CODE END Application */

/************************ (C) COPYRIGHT STMicroelectronics *****END OF FILE****/
